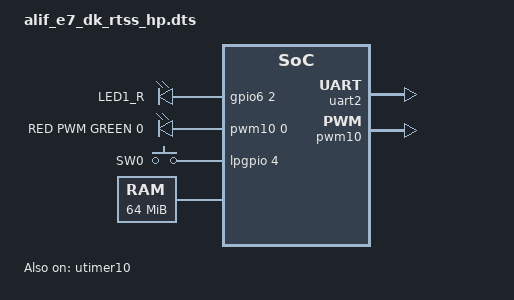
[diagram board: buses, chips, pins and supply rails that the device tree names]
/* Copyright (c) 2024 Alif Semiconductor
 *
 * SPDX-License-Identifier: Apache-2.0
 */
/dts-v1/;

#include <alif/e7_rtss_common.dtsi>
#include <alif/ensemble_rtss_hp.dtsi>
#include <alif/ensemble-pinctrl.dtsi>

/ {
	compatible = "arm,alif-e7-dk-rtss-hp";
	#address-cells = <1>;
	#size-cells = <1>;

	chosen {
		zephyr,flash = &mram_storage;
		zephyr,code-partition = &slot0_partition;
		zephyr,sram = &dtcm;
		zephyr,console = &uart2;
		zephyr,shell-uart = &uart2;
	};

	aliases {
		led0 = &aled0;
		pwm-led0 = &pwm_led0_green;
		sw0 = &button0;
		apssmhu0r = &apss_rtsshe_mhu0_r;
		apssmhu0s = &rtsshe_apss_mhu0_s;
		apssmhu1r = &apss_rtsshe_mhu1_r;
		apssmhu1s = &rtsshe_apss_mhu1_s;
		rtsshemhu0r = &rtsshp_rtsshe_mhu0_r;
		rtsshemhu0s = &rtsshe_rtsshp_mhu0_s;
		rtsshemhu1r = &rtsshp_rtsshe_mhu1_r;
		rtsshemhu1s = &rtsshe_rtsshp_mhu1_s;
	};

	leds {
		compatible = "gpio-leds";
		aled0: led_0 {
			gpios = <&gpio6 2 0>;
			label = "LED1_R";
		};
	};
	pwmleds {
		compatible = "pwm-leds";
		pwm_led0_green: pwm_led_0 {
			pwms = <&pwm10 0 PWM_MSEC(20) PWM_POLARITY_NORMAL>;
			label = "RED PWM GREEN 0";
		};
	};
	buttons {
		compatible = "gpio-keys";
		button0: button_0 {
			gpios = < &lpgpio 4 0 >;
			label = "SW0";
		};
	};
	ext_flash_xip: memory@c0000000 {
		compatible = "zephyr,memory-region";
		reg = <0xc0000000 DT_SIZE_M(64)>;
		zephyr,memory-region = "OSPI1";
	};
};

&uart2 {
	status = "okay";
};

&mram_storage {
	partitions {
		compatible = "fixed-partitions";
		#address-cells = <1>;
		#size-cells = <1>;
		boot_partition: partition@200000 {
			label = "mcuboot";
			reg = <0x00200000 0x00010000>;
			read-only;
		};
		slot0_partition: partition@210000 {
			label = "image-0";
			reg = <0x00210000 0x00010000>;
		};
		slot1_partition: partition@220000 {
			label = "image-1";
			reg = <0x00220000 0x00010000>;
		};
		scratch_partition: partition@230000 {
			label = "image-scratch";
			reg = <0x00230000 0x00010000>;
		};
		storage_partition: partition@240000 {
			label = "storage";
			reg = <0x00240000 DT_SIZE_K(10)>;
		};
	};
};

&utimer10 {
	driver-enable = < ALIF_UTIMER_DRIVER_A_OUTPUT_ENABLE >;
	status = "okay";

	pwm10: pwm {
		pinctrl-0 = < &pinctrl_ut10 >;
		pinctrl-names = "default";
		status = "okay";
	};
};
